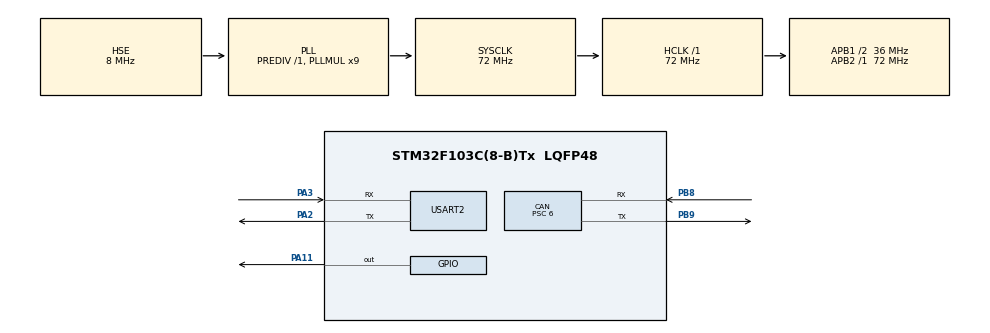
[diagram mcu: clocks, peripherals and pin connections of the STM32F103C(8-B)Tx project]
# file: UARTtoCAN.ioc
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CAN.BS1=CAN_BS1_3TQ
CAN.BS2=CAN_BS2_2TQ
CAN.CalculateTimeBit=1000
CAN.CalculateTimeQuantum=166.66666666666669
CAN.Mode=CAN_MODE_LOOPBACK
CAN.Prescaler=6
CAN.SJW=CAN_SJW_1TQ
Dma.Request0=USART2_RX
Dma.Request1=USART2_TX
Dma.USART2_RX.0.Direction=DMA_PERIPH_TO_MEMORY
Dma.USART2_RX.0.Instance=DMA1_Channel6
Dma.USART2_RX.0.MemDataAlignment=DMA_MDATAALIGN_BYTE
Dma.USART2_RX.0.MemInc=DMA_MINC_ENABLE
Dma.USART2_RX.0.Mode=DMA_NORMAL
Dma.USART2_RX.0.PeriphDataAlignment=DMA_PDATAALIGN_BYTE
Dma.USART2_RX.0.PeriphInc=DMA_PINC_DISABLE
Dma.USART2_RX.0.Priority=DMA_PRIORITY_LOW
Dma.USART2_TX.1.Direction=DMA_MEMORY_TO_PERIPH
Dma.USART2_TX.1.Instance=DMA1_Channel7
Dma.USART2_TX.1.MemDataAlignment=DMA_MDATAALIGN_BYTE
Dma.USART2_TX.1.MemInc=DMA_MINC_ENABLE
Dma.USART2_TX.1.Mode=DMA_NORMAL
Dma.USART2_TX.1.PeriphDataAlignment=DMA_PDATAALIGN_BYTE
Dma.USART2_TX.1.PeriphInc=DMA_PINC_DISABLE
Dma.USART2_TX.1.Priority=DMA_PRIORITY_LOW
Mcu.Family=STM32F1
Mcu.Name=STM32F103C(8-B)Tx
Mcu.Package=LQFP48
NVIC.DMA1_Channel6_IRQn=true\:0\:0\:false\:false\:true\:false\:true
NVIC.DMA1_Channel7_IRQn=true\:0\:0\:false\:false\:true\:false\:true
NVIC.PriorityGroup=NVIC_PRIORITYGROUP_4
NVIC.USART2_IRQn=true\:0\:0\:false\:false\:true\:true\:true
NVIC.USB_LP_CAN1_RX0_IRQn=true\:0\:0\:false\:false\:true\:true\:true
PA11.GPIO_Speed=GPIO_SPEED_FREQ_HIGH
PA11.Signal=GPIO_Output
PA13.Mode=Serial_Wire
PA13.Signal=SYS_JTMS-SWDIO
PA14.Mode=Serial_Wire
PA14.Signal=SYS_JTCK-SWCLK
PA2.Mode=Asynchronous
PA2.Signal=USART2_TX
PA3.Mode=Asynchronous
PA3.Signal=USART2_RX
PB8.Mode=Master
PB8.Signal=CAN_RX
PB9.Mode=Master
PB9.Signal=CAN_TX
PD0-OSC_IN.Mode=HSE-External-Oscillator
PD0-OSC_IN.Signal=RCC_OSC_IN
PD1-OSC_OUT.Mode=HSE-External-Oscillator
PD1-OSC_OUT.Signal=RCC_OSC_OUT
ProjectManager.HeapSize=0x200
ProjectManager.StackSize=0x400
ProjectManager.TargetToolchain=MDK-ARM V5
RCC.AHBFreq_Value=72000000
RCC.APB1CLKDivider=RCC_HCLK_DIV2
RCC.APB1Freq_Value=36000000
RCC.APB1TimFreq_Value=72000000
RCC.APB2Freq_Value=72000000
RCC.APB2TimFreq_Value=72000000
RCC.HCLKFreq_Value=72000000
RCC.PLLMUL=RCC_PLL_MUL9
RCC.PLLSourceVirtual=RCC_PLLSOURCE_HSE
RCC.SYSCLKFreq_VALUE=72000000
RCC.SYSCLKSource=RCC_SYSCLKSOURCE_PLLCLK
RCC.USBFreq_Value=72000000
USART2.VirtualMode=VM_ASYNC
board=custom

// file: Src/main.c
/* USER CODE BEGIN Header */
/**
  ******************************************************************************
  * @file           : main.c
  * @brief          : Main program body
  ******************************************************************************
  * @attention
  *
  * <h2><center>&copy; Copyright (c) 2020 STMicroelectronics.
  * All rights reserved.</center></h2>
  *
  * This software component is licensed by ST under BSD 3-Clause license,
  * the "License"; You may not use this file except in compliance with the
  * License. You may obtain a copy of the License at:
  *                        opensource.org/licenses/BSD-3-Clause
  *
  ******************************************************************************
  */
/* USER CODE END Header */

#include "main.h"
#include "can.h"
#include "dma.h"
#include "usart.h"
#include "gpio.h"

/* USER CODE BEGIN Includes */
#include "stdio.h"
#include "string.h"
/* USER CODE END Includes */

void SystemClock_Config(void);

int main(void)
{
  /* USER CODE BEGIN 1 */
	uint8_t  table_cmd[8]= {0x0f,0x0e,0x0d,0x0c,0x0b,0x0a,0x09,0x08}; //
  /* USER CODE END 1 */

  /* MCU Configuration--------------------------------------------------------*/

  /* Reset of all peripherals, Initializes the Flash interface and the Systick. */
  HAL_Init();

  /* Configure the system clock */
  SystemClock_Config();

  /* Initialize all configured peripherals */
  MX_GPIO_Init();
  MX_DMA_Init();
  MX_CAN_Init();
  MX_USART2_UART_Init();
  /* USER CODE BEGIN 2 */
	CAN_Filter_Config();
	HAL_Delay(10);

  /* USER CODE END 2 */

  /* Infinite loop */
  while (1)
  {
		//HAL_Delay(3000);
		//printf("send\r\n");
		//CAN_SendNormalMsg(&hcan,0x7ff,table_cmd,8);
    /* USER CODE BEGIN 3 */
		if(recv_end_flag==1)
		{
			CAN_SendNormalMsg(&hcan,0x7ff,rx_buffer,rx_len);
			memset(rx_buffer,0,rx_len); //清除数组，需要添加string.h头文件
			rx_len=0;//清除计数
			recv_end_flag=0;//清除接收结束标志位
			HAL_UART_Receive_DMA(&huart2,rx_buffer,BUFFER_SIZE);//重新打开DMA接收
		}
  }
  /* USER CODE END 3 */
}

void SystemClock_Config(void)
{
  RCC_OscInitTypeDef RCC_OscInitStruct = {0};
  RCC_ClkInitTypeDef RCC_ClkInitStruct = {0};

  /** Initializes the CPU, AHB and APB busses clocks
  */
  RCC_OscInitStruct.OscillatorType = RCC_OSCILLATORTYPE_HSE;
  RCC_OscInitStruct.HSEState = RCC_HSE_ON;
  RCC_OscInitStruct.HSEPredivValue = RCC_HSE_PREDIV_DIV1;
  RCC_OscInitStruct.HSIState = RCC_HSI_ON;
  RCC_OscInitStruct.PLL.PLLState = RCC_PLL_ON;
  RCC_OscInitStruct.PLL.PLLSource = RCC_PLLSOURCE_HSE;
  RCC_OscInitStruct.PLL.PLLMUL = RCC_PLL_MUL9;
  if (HAL_RCC_OscConfig(&RCC_OscInitStruct) != HAL_OK)
  {
    Error_Handler();
  }
  /** Initializes the CPU, AHB and APB busses clocks
  */
  RCC_ClkInitStruct.ClockType = RCC_CLOCKTYPE_HCLK|RCC_CLOCKTYPE_SYSCLK
                              |RCC_CLOCKTYPE_PCLK1|RCC_CLOCKTYPE_PCLK2;
  RCC_ClkInitStruct.SYSCLKSource = RCC_SYSCLKSOURCE_PLLCLK;
  RCC_ClkInitStruct.AHBCLKDivider = RCC_SYSCLK_DIV1;
  RCC_ClkInitStruct.APB1CLKDivider = RCC_HCLK_DIV2;
  RCC_ClkInitStruct.APB2CLKDivider = RCC_HCLK_DIV1;

  if (HAL_RCC_ClockConfig(&RCC_ClkInitStruct, FLASH_LATENCY_2) != HAL_OK)
  {
    Error_Handler();
  }
}

void Error_Handler(void)
{
}

/************************ (C) COPYRIGHT STMicroelectronics *****END OF FILE****/
